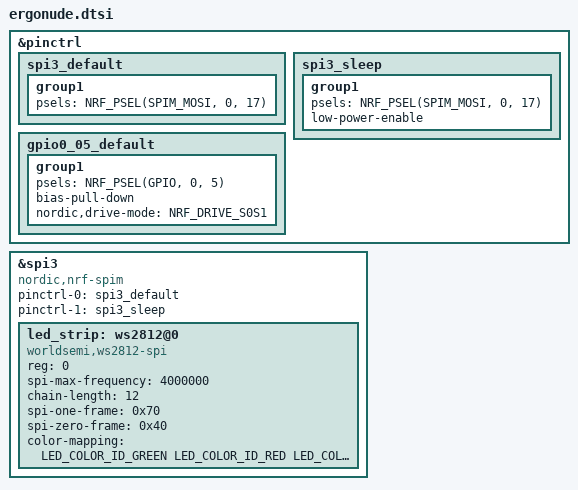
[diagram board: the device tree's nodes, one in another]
#include <dt-bindings/pinctrl/nrf-pinctrl.h>

&pinctrl {
    spi3_default: spi3_default {
        group1 {
            psels = <NRF_PSEL(SPIM_MOSI, 0, 17)>;
        };
    };
    spi3_sleep: spi3_sleep {
        group1 {
            psels = <NRF_PSEL(SPIM_MOSI, 0, 17)>;
            low-power-enable;
        };
    };
    gpio0_05_default: gpio0_05_default {
        group1 {
            psels = <NRF_PSEL(GPIO, 0, 5)>;
            bias-pull-down;  // 与你的 row 配置一致
            nordic,drive-mode = <NRF_DRIVE_S0S1>;  // 标准驱动，或 <NRF_DRIVE_H0H1> 高驱动
        };
    };
};

&spi3 {
    compatible = "nordic,nrf-spim";
    status = "okay";
    pinctrl-0 = <&spi3_default>;
    pinctrl-1 = <&spi3_sleep>;
    pinctrl-names = "default", "sleep";

    led_strip: ws2812@0 {
        compatible = "worldsemi,ws2812-spi";
        reg = <0>;
        spi-max-frequency = <4000000>;
        chain-length = <12>;
        spi-one-frame = <0x70>;
        spi-zero-frame = <0x40>;
        color-mapping = <LED_COLOR_ID_GREEN LED_COLOR_ID_RED LED_COLOR_ID_BLUE>;
    };
};
